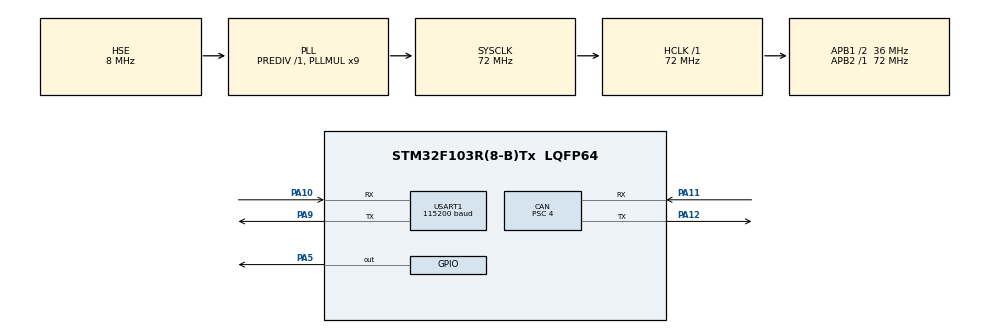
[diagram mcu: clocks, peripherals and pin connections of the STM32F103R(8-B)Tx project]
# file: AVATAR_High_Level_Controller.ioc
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CAN.BS1=CAN_BS1_15TQ
CAN.BS2=CAN_BS2_2TQ
CAN.CalculateBaudRate=500000
CAN.CalculateTimeBit=2000
CAN.CalculateTimeQuantum=111.11111111111111
CAN.Prescaler=4
FREERTOS.Tasks01=defaultTask,0,128,StartDefaultTask,Default,NULL,Dynamic,NULL,NULL;uartTask,-3,128,UARTTaskFunction,Default,NULL,Dynamic,NULL,NULL;canTask,-3,128,CANTaskFunction,Default,NULL,Dynamic,NULL,NULL
FREERTOS.configUSE_NEWLIB_REENTRANT=1
Mcu.Family=STM32F1
Mcu.Name=STM32F103R(8-B)Tx
Mcu.Package=LQFP64
NVIC.PriorityGroup=NVIC_PRIORITYGROUP_4
NVIC.TIM1_BRK_IRQn=true\:5\:0\:false\:false\:true\:true\:true\:true\:true
NVIC.TIM1_CC_IRQn=true\:5\:0\:false\:false\:true\:true\:true\:true\:true
NVIC.TIM1_TRG_COM_IRQn=true\:5\:0\:false\:false\:true\:true\:true\:true\:true
NVIC.TIM1_UP_IRQn=true\:5\:0\:false\:false\:true\:true\:true\:true\:true
NVIC.TIM4_IRQn=true\:15\:0\:false\:false\:true\:false\:false\:true\:true
NVIC.TimeBase=TIM4_IRQn
NVIC.TimeBaseIP=TIM4
NVIC.USART1_IRQn=true\:5\:0\:false\:false\:true\:true\:true\:true\:true
NVIC.USB_LP_CAN1_RX0_IRQn=true\:5\:0\:false\:false\:true\:true\:true\:true\:true
PA10.Mode=Asynchronous
PA10.Signal=USART1_RX
PA11.Mode=CAN_Activate
PA11.Signal=CAN_RX
PA12.Mode=CAN_Activate
PA12.Signal=CAN_TX
PA13.Mode=Serial_Wire
PA13.Signal=SYS_JTMS-SWDIO
PA14.Mode=Serial_Wire
PA14.Signal=SYS_JTCK-SWCLK
PA5.Signal=GPIO_Output
PA9.Mode=Asynchronous
PA9.Signal=USART1_TX
PD0-OSC_IN.Mode=HSE-External-Oscillator
PD0-OSC_IN.Signal=RCC_OSC_IN
PD1-OSC_OUT.Mode=HSE-External-Oscillator
PD1-OSC_OUT.Signal=RCC_OSC_OUT
ProjectManager.HeapSize=0x200
ProjectManager.StackSize=0x400
ProjectManager.TargetToolchain=STM32CubeIDE
RCC.AHBFreq_Value=72000000
RCC.APB1CLKDivider=RCC_HCLK_DIV2
RCC.APB1Freq_Value=36000000
RCC.APB1TimFreq_Value=72000000
RCC.APB2Freq_Value=72000000
RCC.APB2TimFreq_Value=72000000
RCC.HCLKFreq_Value=72000000
RCC.PLLMUL=RCC_PLL_MUL9
RCC.PLLSourceVirtual=RCC_PLLSOURCE_HSE
RCC.SYSCLKFreq_VALUE=72000000
RCC.SYSCLKSource=RCC_SYSCLKSOURCE_PLLCLK
RCC.USBFreq_Value=72000000
TIM1.Period=10-1
TIM1.Prescaler=7200-1
USART1.BaudRate=115200
USART1.VirtualMode=VM_ASYNC
VP_FREERTOS_VS_CMSIS_V1.Mode=CMSIS_V1
VP_SYS_VS_tim4.Mode=TIM4
VP_TIM1_VS_ClockSourceINT.Mode=Internal
board=custom

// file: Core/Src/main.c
/* USER CODE BEGIN Header */
/**
  ******************************************************************************
  * @file           : main.c
  * @brief          : Main program body
  ******************************************************************************
  * @attention
  *
  * Copyright (c) 2024 STMicroelectronics.
  * All rights reserved.
  *
  * This software is licensed under terms that can be found in the LICENSE file
  * in the root directory of this software component.
  * If no LICENSE file comes with this software, it is provided AS-IS.
  *
  ******************************************************************************
  */
/* USER CODE END Header */
#include "main.h"
#include "cmsis_os.h"

/* USER CODE BEGIN Includes */
#include "high_level_controller_main.h"
#include "high_level_controller_callbacks.h"
/* USER CODE END Includes */

CAN_HandleTypeDef hcan;

TIM_HandleTypeDef htim1;

UART_HandleTypeDef huart1;

osThreadId defaultTaskHandle;
osThreadId uartTaskHandle;
osThreadId canTaskHandle;

void SystemClock_Config(void);
static void MX_GPIO_Init(void);
static void MX_USART1_UART_Init(void);
static void MX_CAN_Init(void);
static void MX_TIM1_Init(void);
void StartDefaultTask(void const * argument);
void UARTTaskFunction(void const * argument);
void CANTaskFunction(void const * argument);

int main(void)
{

  /* MCU Configuration--------------------------------------------------------*/

  /* Reset of all peripherals, Initializes the Flash interface and the Systick. */
  HAL_Init();

  /* Configure the system clock */
  SystemClock_Config();

  /* Initialize all configured peripherals */
  MX_GPIO_Init();
  MX_USART1_UART_Init();
  MX_CAN_Init();
  MX_TIM1_Init();
  /* USER CODE BEGIN 2 */

  Start();

  /* USER CODE END 2 */

  /* Create the thread(s) */
  /* definition and creation of defaultTask */
  osThreadDef(defaultTask, StartDefaultTask, osPriorityNormal, 0, 128);
  defaultTaskHandle = osThreadCreate(osThread(defaultTask), NULL);

  /* definition and creation of uartTask */
  osThreadDef(uartTask, UARTTaskFunction, osPriorityIdle, 0, 128);
  uartTaskHandle = osThreadCreate(osThread(uartTask), NULL);

  /* definition and creation of canTask */
  osThreadDef(canTask, CANTaskFunction, osPriorityIdle, 0, 128);
  canTaskHandle = osThreadCreate(osThread(canTask), NULL);

  /* Start scheduler */
  osKernelStart();

  /* We should never get here as control is now taken by the scheduler */

  /* Infinite loop */
  while (1)
  {

  }
}

void SystemClock_Config(void)
{
  RCC_OscInitTypeDef RCC_OscInitStruct = {0};
  RCC_ClkInitTypeDef RCC_ClkInitStruct = {0};

  /** Initializes the RCC Oscillators according to the specified parameters
  * in the RCC_OscInitTypeDef structure.
  */
  RCC_OscInitStruct.OscillatorType = RCC_OSCILLATORTYPE_HSE;
  RCC_OscInitStruct.HSEState = RCC_HSE_ON;
  RCC_OscInitStruct.HSEPredivValue = RCC_HSE_PREDIV_DIV1;
  RCC_OscInitStruct.HSIState = RCC_HSI_ON;
  RCC_OscInitStruct.PLL.PLLState = RCC_PLL_ON;
  RCC_OscInitStruct.PLL.PLLSource = RCC_PLLSOURCE_HSE;
  RCC_OscInitStruct.PLL.PLLMUL = RCC_PLL_MUL9;
  if (HAL_RCC_OscConfig(&RCC_OscInitStruct) != HAL_OK)
  {
    Error_Handler();
  }

  /** Initializes the CPU, AHB and APB buses clocks
  */
  RCC_ClkInitStruct.ClockType = RCC_CLOCKTYPE_HCLK|RCC_CLOCKTYPE_SYSCLK
                              |RCC_CLOCKTYPE_PCLK1|RCC_CLOCKTYPE_PCLK2;
  RCC_ClkInitStruct.SYSCLKSource = RCC_SYSCLKSOURCE_PLLCLK;
  RCC_ClkInitStruct.AHBCLKDivider = RCC_SYSCLK_DIV1;
  RCC_ClkInitStruct.APB1CLKDivider = RCC_HCLK_DIV2;
  RCC_ClkInitStruct.APB2CLKDivider = RCC_HCLK_DIV1;

  if (HAL_RCC_ClockConfig(&RCC_ClkInitStruct, FLASH_LATENCY_2) != HAL_OK)
  {
    Error_Handler();
  }
}

static void MX_CAN_Init(void)
{

  hcan.Instance = CAN1;
  hcan.Init.Prescaler = 4;
  hcan.Init.Mode = CAN_MODE_NORMAL;
  hcan.Init.SyncJumpWidth = CAN_SJW_1TQ;
  hcan.Init.TimeSeg1 = CAN_BS1_15TQ;
  hcan.Init.TimeSeg2 = CAN_BS2_2TQ;
  hcan.Init.TimeTriggeredMode = DISABLE;
  hcan.Init.AutoBusOff = DISABLE;
  hcan.Init.AutoWakeUp = DISABLE;
  hcan.Init.AutoRetransmission = DISABLE;
  hcan.Init.ReceiveFifoLocked = DISABLE;
  hcan.Init.TransmitFifoPriority = DISABLE;
  if (HAL_CAN_Init(&hcan) != HAL_OK)
  {
    Error_Handler();
  }

}

static void MX_TIM1_Init(void)
{

  TIM_ClockConfigTypeDef sClockSourceConfig = {0};
  TIM_MasterConfigTypeDef sMasterConfig = {0};

  htim1.Instance = TIM1;
  htim1.Init.Prescaler = 7200-1;
  htim1.Init.CounterMode = TIM_COUNTERMODE_UP;
  htim1.Init.Period = 10-1;
  htim1.Init.ClockDivision = TIM_CLOCKDIVISION_DIV1;
  htim1.Init.RepetitionCounter = 0;
  htim1.Init.AutoReloadPreload = TIM_AUTORELOAD_PRELOAD_DISABLE;
  if (HAL_TIM_Base_Init(&htim1) != HAL_OK)
  {
    Error_Handler();
  }
  sClockSourceConfig.ClockSource = TIM_CLOCKSOURCE_INTERNAL;
  if (HAL_TIM_ConfigClockSource(&htim1, &sClockSourceConfig) != HAL_OK)
  {
    Error_Handler();
  }
  sMasterConfig.MasterOutputTrigger = TIM_TRGO_RESET;
  sMasterConfig.MasterSlaveMode = TIM_MASTERSLAVEMODE_DISABLE;
  if (HAL_TIMEx_MasterConfigSynchronization(&htim1, &sMasterConfig) != HAL_OK)
  {
    Error_Handler();
  }

}

static void MX_USART1_UART_Init(void)
{

  huart1.Instance = USART1;
  huart1.Init.BaudRate = 115200;
  huart1.Init.WordLength = UART_WORDLENGTH_8B;
  huart1.Init.StopBits = UART_STOPBITS_1;
  huart1.Init.Parity = UART_PARITY_NONE;
  huart1.Init.Mode = UART_MODE_TX_RX;
  huart1.Init.HwFlowCtl = UART_HWCONTROL_NONE;
  huart1.Init.OverSampling = UART_OVERSAMPLING_16;
  if (HAL_UART_Init(&huart1) != HAL_OK)
  {
    Error_Handler();
  }

}

static void MX_GPIO_Init(void)
{
  GPIO_InitTypeDef GPIO_InitStruct = {0};

  /* GPIO Ports Clock Enable */
  __HAL_RCC_GPIOD_CLK_ENABLE();
  __HAL_RCC_GPIOA_CLK_ENABLE();

  /*Configure GPIO pin Output Level */
  HAL_GPIO_WritePin(GPIOA, GPIO_PIN_5, GPIO_PIN_RESET);

  /*Configure GPIO pin : PA5 */
  GPIO_InitStruct.Pin = GPIO_PIN_5;
  GPIO_InitStruct.Mode = GPIO_MODE_OUTPUT_PP;
  GPIO_InitStruct.Pull = GPIO_NOPULL;
  GPIO_InitStruct.Speed = GPIO_SPEED_FREQ_LOW;
  HAL_GPIO_Init(GPIOA, &GPIO_InitStruct);

}

void StartDefaultTask(void const * argument)
{
  /* USER CODE BEGIN 5 */
  /* Infinite loop */
  for(;;)
  {
	  Update();
	  osDelay(1);
  }
  /* USER CODE END 5 */
}

void UARTTaskFunction(void const * argument)
{
  /* USER CODE BEGIN UARTTaskFunction */
  /* Infinite loop */
  for(;;)
  {
	  UART_Callback();
//	  osDelay(1);
  }
  /* USER CODE END UARTTaskFunction */
}

void CANTaskFunction(void const * argument)
{
  /* USER CODE BEGIN CANTaskFunction */
  /* Infinite loop */
  for(;;)
  {
	  CAN_Callback();
//	  osDelay(1);
  }
  /* USER CODE END CANTaskFunction */
}

void HAL_TIM_PeriodElapsedCallback(TIM_HandleTypeDef *htim)
{
  if (htim->Instance == TIM4) {
    HAL_IncTick();
  }
  /* USER CODE BEGIN Callback 1 */
  On_Timer_Tick(htim);
  /* USER CODE END Callback 1 */
}

void Error_Handler(void)
{
  __disable_irq();
  while (1)
  {
  }
}
